# S32K342_M7 register map
Vendor: NXP Semiconductors; File version: 1.5
CPU: CM7 r0p1, little endian, MPU, FPU, VTOR, 4 interrupt priority bits
Registers are 32-bit, read-write, reset 0x0 unless marked. A register's access mark holds for its fields unless they carry their own. Offsets are from the block's base; [hi:lo] are bit positions; {n}, {i} and the like mark numbered series; 'fields as' and 'values as' point back to an identical list.

## QUADSPI
Base 0x404CC000
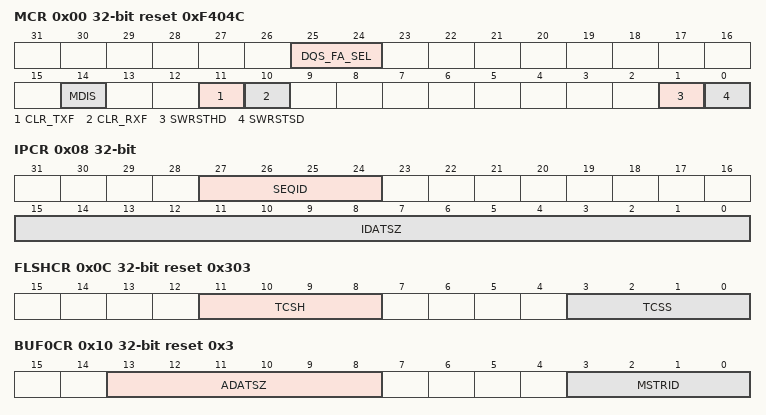
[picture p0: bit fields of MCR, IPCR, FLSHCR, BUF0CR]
0x00 MCR reset 0xF404C — Module Configuration Register
  [25:24] DQS_FA_SEL — DQS clock for sampling read data at flash memory A
  [14] MDIS — Module disable
    0=id0 (Enable QuadSPI clocks); 1=id1 (Allow external logic to disable QuadSPI clocks)
  [11] CLR_TXF — Clear TX FIFO/buffer
    0=id0 (No action); 1=id1 (Read and write pointers of the TX buffer are reset to 0 and TBSR[TRCTR] is reset to 0.)
  [10] CLR_RXF — Clear RX FIFO
    0=id0 (No action); 1=id1 (Read and write pointers of the RX buffer are reset to 0 and RBSR[RDBFL] is reset to 0.)
  [1] SWRSTHD — Software reset for AHB domain
  [0] SWRSTSD — Software reset for serial flash memory domain
0x08 IPCR — IP Configuration Register
  [27:24] SEQID — Points to a sequence in the LUT
  [15:0] IDATSZ — IP data transfer size
0x0C FLSHCR reset 0x303 — Flash Memory Configuration Register
  [11:8] TCSH — Serial flash memory CS hold time
  [3:0] TCSS — Serial flash memory CS setup time
0x10 BUF0CR reset 0x3 — Buffer 0 Configuration Register
  [13:8] ADATSZ — AHB data transfer size
  [3:0] MSTRID — Master ID
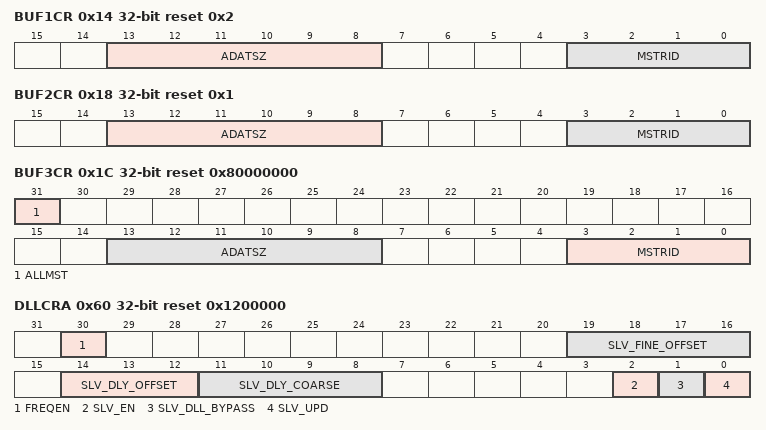
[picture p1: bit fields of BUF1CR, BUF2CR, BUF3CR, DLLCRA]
0x14 BUF1CR reset 0x2 — Buffer 1 Configuration Register
  [13:8] ADATSZ — AHB data transfer size
  [3:0] MSTRID — Master ID
0x18 BUF2CR reset 0x1 — Buffer 2 Configuration Register
  [13:8] ADATSZ — AHB data transfer size
  [3:0] MSTRID — Master ID
0x1C BUF3CR reset 0x80000000 — Buffer 3 Configuration Register
  [31] ALLMST — All master enable
  [13:8] ADATSZ — AHB data transfer size
  [3:0] MSTRID — Master ID
0x20 BFGENCR — Buffer Generic Configuration Register
  [15:12] SEQID — Points to a sequence in the LUT
0x24 SOCCR — SOC Configuration Register
  [31:0] SOCCFG — SOC configuration
{0x30+4i} BUF{i}IND (i=0..2) — Buffer {i} Top Index Register
  [8:3] TPINDX{i} — Top index of buffer {i}
0x60 DLLCRA reset 0x1200000 — DLL Flash Memory A Configuration Register
  [30] FREQEN — Frequency enable
    0=id0 (Selects delay chain for low frequency of operation); 1=id1 (Selects delay chain for high frequency of operation)
  [19:16] SLV_FINE_OFFSET — Fine offset delay elements in incoming DQS
  [14:12] SLV_DLY_OFFSET — T/16 offset delay elements in incoming DQS
  [11:8] SLV_DLY_COARSE — Delay elements in each delay tap
  [2] SLV_EN — Slave enable
    0=id0 (DLL slave logic remains in reset, and its value should be 0 for at least three flash memory clock cycles for reset.); 1=id1 (Enables DQS slave delay chain, and should be 1 before any slave configuration settings take place.)
  [1] SLV_DLL_BYPASS — Slave DLL bypass
    0=id0 (Disables manual selection of coarse delays in the slave delay chain.); 1=id1 (Enables selection of number of delays in each slave delay tap, based on DLLCRA[SLV_DLY_COARSE].)
  [0] SLV_UPD — Slave update
    0=id0 (Disables any further update on DQS slave delay chain.); 1=id1 (Updates the DQS slave delay chain with either ref-delay or bypass slave delay value, and should be set in the absence of the DQS clock.)
0x100 SFAR — Serial Flash Memory Address Register
  [31:0] SFADR — Serial flash memory address
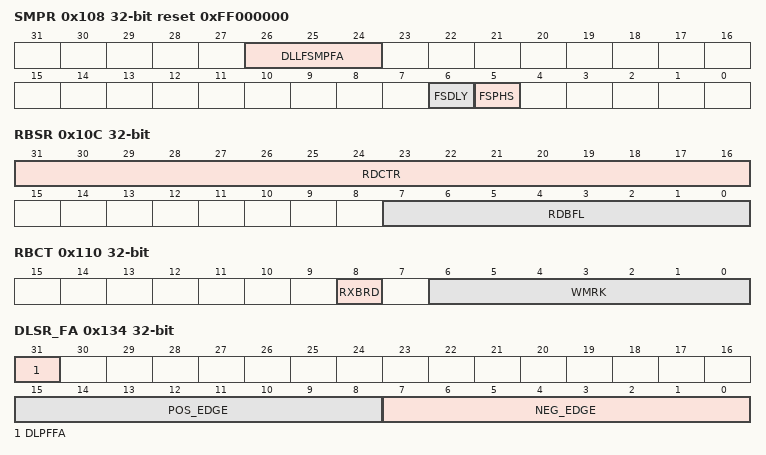
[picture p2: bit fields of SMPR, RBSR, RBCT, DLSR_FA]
0x108 SMPR reset 0xFF000000 — Sampling Register
  [26:24] DLLFSMPFA — Selects the nth tap provided by slave delay chain for flash memory A
  [6] FSDLY — Full speed delay selection for SDR instructions
  [5] FSPHS — Full-speed phase selection for SDR instructions
0x10C RBSR ro — RX Buffer Status Register
  [31:16] RDCTR — Read counter
  [7:0] RDBFL — RX buffer fill level
0x110 RBCT — RX Buffer Control Register
  [8] RXBRD — RX buffer readout
  [6:0] WMRK — RX buffer watermark
0x134 DLSR_FA ro — Data Learning Status Flash Memory A Register
  [31] DLPFFA — Data learning pattern fail
  [15:8] POS_EDGE — DLP positive edge match signature for flash memory A
  [7:0] NEG_EDGE — DLP negative edge match signature for flash memory A
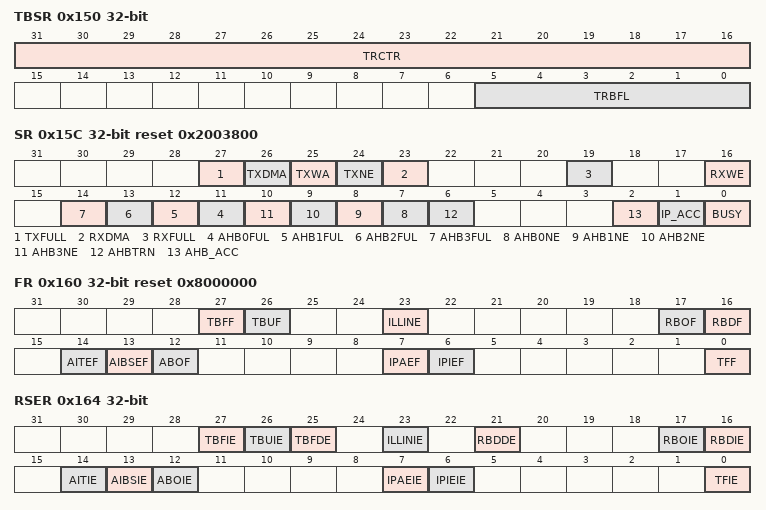
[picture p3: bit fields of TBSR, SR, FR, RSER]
0x150 TBSR ro — TX Buffer Status Register
  [31:16] TRCTR — Transmit counter
  [5:0] TRBFL — TX buffer fill level
0x154 TBDR — TX Buffer Data Register
  [31:0] TXDATA
0x158 TBCT — TX Buffer Control Register
  [4:0] WMRK — Watermark for TX buffer
0x15C SR ro reset 0x2003800 — Status Register
  [27] TXFULL — TX buffer full
  [26] TXDMA
  [25] TXWA — TX buffer watermark available
  [24] TXNE — TX buffer not empty
  [23] RXDMA — RX buffer DMA
  [19] RXFULL — RX buffer full
  [16] RXWE — RX buffer watermark exceeded
  [n+11] AHB{n}FUL (n=0..3) — AHB {n} buffer full
  [n+7] AHB{n}NE (n=0..3) — AHB {n} buffer not empty
  [6] AHBTRN — AHB access transaction pending
  [2] AHB_ACC — AHB read access
  [1] IP_ACC — IP access
  [0] BUSY — Module busy
0x160 FR reset 0x8000000 write-1-clears — Flag Register
  [27] TBFF write-1-clears — TX buffer fill flag
  [26] TBUF write-1-clears — TX buffer underrun flag
  [23] ILLINE write-1-clears — Illegal instruction error flag
  [17] RBOF write-1-clears — RX buffer overflow flag
  [16] RBDF write-1-clears — RX buffer drain flag
  [14] AITEF write-1-clears — AHB illegal transaction error flag
  [13] AIBSEF write-1-clears — AHB illegal burst size error flag
  [12] ABOF write-1-clears — AHB buffer overflow flag
  [7] IPAEF write-1-clears — IP command trigger during AHB access error flag
  [6] IPIEF write-1-clears — IP command trigger could not be executed error flag
  [0] TFF write-1-clears — IP command transaction finished flag
0x164 RSER — Interrupt and DMA Request Select and Enable Register
  [27] TBFIE — TX buffer fill interrupt enable flag
    0=id0 (No TBFF interrupt is generated.); 1=id1 (TBFF interrupt is generated.)
  [26] TBUIE — TX buffer underrun interrupt enable flag
    0=id0 (No TBUF interrupt is generated); 1=id1 (TBUF interrupt is generated)
  [25] TBFDE — TX buffer fill DMA enable
    0=id0 (No DMA request is generated); 1=id1 (DMA request is generated)
  [23] ILLINIE — Illegal instruction error interrupt enable
    0=id0 (No ILLINE interrupt is generated.); 1=id1 (ILLINE interrupt is generated.)
  [21] RBDDE — RX buffer drain DMA enable
    0=id0 (No DMA request is generated.); 1=id1 (DMA request is generated.)
  [17] RBOIE — RX buffer overflow interrupt enable
    0=id0 (No RBOF interrupt is generated.); 1=id1 (RBOF interrupt is generated.)
  [16] RBDIE — RX buffer drain interrupt enable
    0=id0 (No RBDF interrupt is generated.); 1=id1 (RBDF Interrupt is generated.)
  [14] AITIE — AHB illegal transaction interrupt enable flag
    0=id0 (No AITEF interrupt is generated.); 1=id1 (AITEF interrupt is generated.)
  [13] AIBSIE — AHB illegal burst size interrupt enable flag
    0=id0 (No AIBSEF interrupt is generated.); 1=id1 (AIBSEF interrupt is generated.)
  [12] ABOIE — AHB buffer overflow interrupt enable flag
    0=id0 (No ABOF interrupt is generated.); 1=id1 (ABOF interrupt is generated.)
  [7] IPAEIE — IP command trigger during AHB read access error interrupt enable flag
    0=id0 (No IPAEF interrupt is generated); 1=id1 (IPAEF interrupt is generated)
  [6] IPIEIE — IP command trigger during IP access error interrupt enable flag
    0=id0 (No IPIEF interrupt is generated); 1=id1 (IPIEF interrupt is generated)
  [0] TFIE — Transaction finished interrupt enable flag
    0=id0 (No TFF interrupt is generated.); 1=id1 (TFF interrupt is generated.)
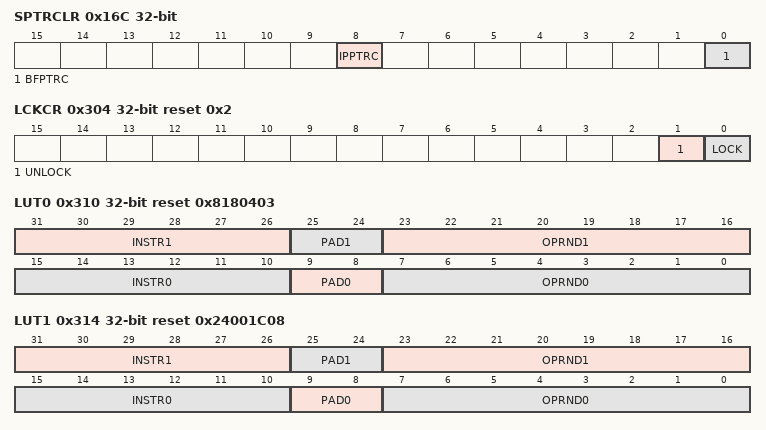
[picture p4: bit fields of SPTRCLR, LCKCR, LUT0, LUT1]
0x16C SPTRCLR — Sequence Pointer Clear Register
  [8] IPPTRC — IP pointer clear
    1=id1 (Clears the sequence pointer for IP accesses as defined in IPCR.)
  [0] BFPTRC — Buffer pointer clear
    1=id1 (Clears the sequence pointer for AHB read accesses as defined in BFGENCR.)
0x180 SFA1AD reset 0x70000000 — Serial Flash Memory A1 Top Address Register
  [31:10] TPADA1 — Top address for serial flash memory A1
0x184 SFA2AD reset 0x70000000 — Serial Flash Memory A2 Top Address Register
  [31:10] TPADA2 — Top address for serial flash memory A2
0x188 SFB1AD reset 0x70000000 — Serial Flash Memory B1 Top Address Register
  [31:10] TPADB1 — Top address for serial flash memory B1.
0x18C SFB2AD reset 0x70000000 — Serial Flash Memory B2 Top Address Register
  [31:10] TPADB2 — Top address for serial flash memory B2.
{0x200+4i} RBDR[{i}] (i=0..63) ro — RX Buffer Data Register
  [31:0] RXDATA
0x300 LUTKEY reset 0x5AF05AF0
  [31:0] KEY — Key to lock or unlock the LUT
0x304 LCKCR reset 0x2 — LUT Lock Configuration Register
  [1] UNLOCK — Unlock LUT
  [0] LOCK — Lock LUT
0x310 LUT0 reset 0x8180403 — LUT Register
  [31:26] INSTR1 — Instruction 1
  [25:24] PAD1 — Pad information for INSTR1
    0=id00 (1 Pad); 1=id01 (2 Pads); 2=id10 (4 Pads); 3=id11 (NA)
  [23:16] OPRND1 — Operand for INSTR1
  [15:10] INSTR0 — Instruction 0
  [9:8] PAD0 — Pad information for INSTR0
    values as PAD1
  [7:0] OPRND0 — Operand for INSTR0
0x314 LUT1 reset 0x24001C08 — LUT Register
  fields as LUT0
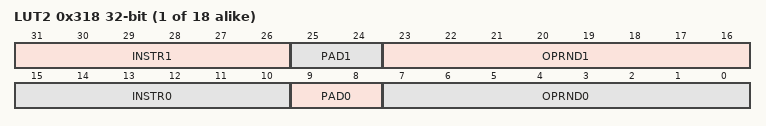
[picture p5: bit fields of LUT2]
{0x310+4i} LUT{i} (i=2..19) — LUT Register
  fields as LUT0
